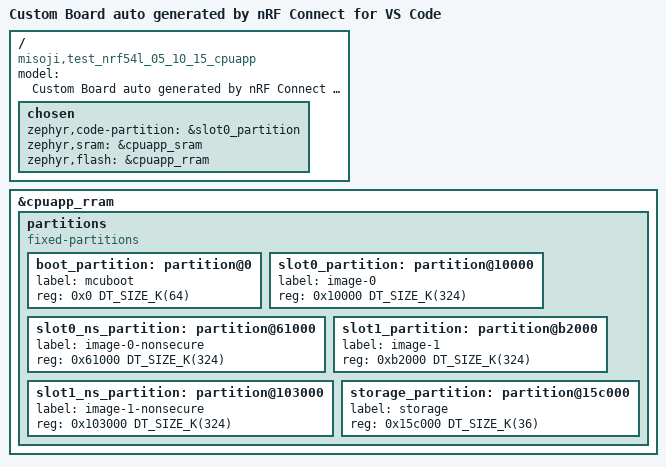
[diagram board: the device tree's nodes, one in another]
/dts-v1/;
#include <nordic/nrf54l15_cpuapp.dtsi>
#include "test_nrf54l_05_10_15_cpuapp_common.dtsi"

/ {
	model = "Custom Board auto generated by nRF Connect for VS Code";
	compatible = "misoji,test_nrf54l_05_10_15_cpuapp";

	chosen {
		zephyr,code-partition = &slot0_partition;
		zephyr,sram = &cpuapp_sram;
		zephyr,flash = &cpuapp_rram;
	};
};

&cpuapp_rram {
	partitions {
		compatible = "fixed-partitions";
		#address-cells = <1>;
		#size-cells = <1>;
		boot_partition: partition@0 {
			label = "mcuboot";
			reg = <0x0 DT_SIZE_K(64)>;
		};
		slot0_partition: partition@10000 {
			label = "image-0";
			reg = <0x10000 DT_SIZE_K(324)>;
		};
		slot0_ns_partition: partition@61000 {
			label = "image-0-nonsecure";
			reg = <0x61000 DT_SIZE_K(324)>;
		};
		slot1_partition: partition@b2000 {
			label = "image-1";
			reg = <0xb2000 DT_SIZE_K(324)>;
		};
		slot1_ns_partition: partition@103000 {
			label = "image-1-nonsecure";
			reg = <0x103000 DT_SIZE_K(324)>;
		};
		/* 32k from 0x154000 to 0x15bfff reserved for TF-M partitions */
		storage_partition: partition@15c000 {
			label = "storage";
			reg = <0x15c000 DT_SIZE_K(36)>;
		};
	};
};


//my nRF54L10

// /* FLPR not supported yet, give all SRAM and RRAM to the APP core */
// &cpuapp_sram {
// 	reg = <0x20000000 DT_SIZE_K(192)>;
// 	ranges = <0x0 0x20000000 DT_SIZE_K(192)>;
// };

// &cpuapp_rram {
// 	reg = <0x0 DT_SIZE_K(1022)>;
// };

// /* These partition sizes assume no FLPR area in RRAM */
// &cpuapp_rram {
// 	partitions {
// 		compatible = "fixed-partitions";
// 		#address-cells = <1>;
// 		#size-cells = <1>;
// 		boot_partition: partition@0 {
// 			label = "mcuboot";
// 			reg = <0x0 DT_SIZE_K(64)>;
// 		};
// 		slot0_partition: partition@10000 {
// 			label = "image-0";
// 			reg = <0x10000 DT_SIZE_K(230)>;
// 		};
// 		slot0_ns_partition: partition@49800 {
// 			label = "image-0-nonsecure";
// 			reg = <0x49800 DT_SIZE_K(230)>;
// 		};
// 		slot1_partition: partition@83000 {
// 			label = "image-1";
// 			reg = <0x83000 DT_SIZE_K(230)>;
// 		};
// 		slot1_ns_partition: partition@bc800 {
// 			label = "image-1-nonsecure";
// 			reg = <0xbc800 DT_SIZE_K(230)>;
// 		};
// 		storage_partition: partition@f6000 {
// 			label = "storage";
// 			reg = <0xf6000 DT_SIZE_K(38)>;
// 		};
// 	};
// };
